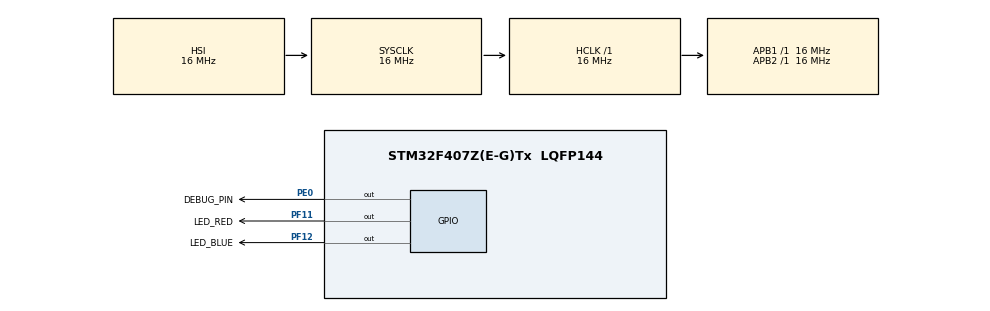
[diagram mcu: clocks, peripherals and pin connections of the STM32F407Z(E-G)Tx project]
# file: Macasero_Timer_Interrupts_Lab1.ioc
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Mcu.Family=STM32F4
Mcu.Name=STM32F407Z(E-G)Tx
Mcu.Package=LQFP144
NVIC.PriorityGroup=NVIC_PRIORITYGROUP_4
NVIC.TIM2_IRQn=true\:0\:0\:false\:false\:true\:true\:true\:true
NVIC.TIM3_IRQn=true\:0\:0\:false\:false\:true\:true\:true\:true
PE0.GPIO_Label=DEBUG_PIN
PE0.Signal=GPIO_Output
PF11.GPIO_Label=LED_RED
PF11.Signal=GPIO_Output
PF12.GPIO_Label=LED_BLUE
PF12.Signal=GPIO_Output
ProjectManager.HeapSize=0x200
ProjectManager.StackSize=0x400
ProjectManager.TargetToolchain=STM32CubeIDE
RCC.AHBFreq_Value=16000000
RCC.APB1Freq_Value=16000000
RCC.APB2Freq_Value=16000000
RCC.CortexFreq_Value=16000000
RCC.HSE_VALUE=25000000
RCC.HSI_VALUE=16000000
RCC.LSE_VALUE=32768
RCC.SYSCLKFreq_VALUE=16000000
RCC.VCOOutputFreq_Value=192000000
TIM2.Period=9999
TIM2.Prescaler=8399
TIM3.Period=4999
TIM3.Prescaler=8399
VP_TIM2_VS_ClockSourceINT.Mode=Internal
VP_TIM3_VS_ClockSourceINT.Mode=Internal
board=custom

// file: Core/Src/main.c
/* USER CODE BEGIN Header */
/**
  ******************************************************************************
  * @file           : main.c
  * @brief          : Main program body with DWT cycle counter
  ******************************************************************************
  * @attention
  *
  * Copyright (c) 2026 STMicroelectronics.
  * All rights reserved.
  *
  * This software is licensed under terms that can be found in the LICENSE file
  * in the root directory of this software component.
  * If no LICENSE file comes with this software, it is provided AS-IS.
  *
  ******************************************************************************
  */
/* USER CODE END Header */

#include "main.h"

TIM_HandleTypeDef htim2;
TIM_HandleTypeDef htim3;

/* USER CODE BEGIN PV */
/// Flags for foreground/background communication
volatile uint8_t task_adc_ready = 0;
volatile uint8_t task_display_ready = 0;
volatile uint32_t tick_count = 0;

/* USER CODE END PV */

void SystemClock_Config(void);
static void MX_GPIO_Init(void);
static void MX_TIM2_Init(void);
static void MX_TIM3_Init(void);

/* USER CODE BEGIN 0 */
// ------------------- DWT Cycle Counter for Microsecond Timing -------------------
static void DWT_Init(void) {
    if (!(CoreDebug->DEMCR & CoreDebug_DEMCR_TRCENA_Msk)) {
        CoreDebug->DEMCR |= CoreDebug_DEMCR_TRCENA_Msk; // Enable trace
    }
    DWT->CYCCNT = 0;            // Reset cycle counter
    DWT->CTRL |= DWT_CTRL_CYCCNTENA_Msk; // Enable cycle counter
}

static uint32_t DWT_GetMicroseconds(void) {
    return DWT->CYCCNT / (SystemCoreClock / 1000000);
}
// --------------------------------------------------------------------------------

// Timer Interrupt Callback
void HAL_TIM_PeriodElapsedCallback(TIM_HandleTypeDef *htim)
{
    if (htim->Instance == TIM2)
    {
        uint32_t start_us = DWT_GetMicroseconds();

        HAL_GPIO_WritePin(DEBUG_PIN_GPIO_Port, DEBUG_PIN_Pin, GPIO_PIN_SET);
        HAL_GPIO_TogglePin(LED_RED_GPIO_Port, LED_RED_Pin);
        task_adc_ready = 1;

        HAL_GPIO_WritePin(DEBUG_PIN_GPIO_Port, DEBUG_PIN_Pin, GPIO_PIN_RESET);

        uint32_t elapsed_us = DWT_GetMicroseconds() - start_us;
        // You can store or print elapsed_us if needed
    }
}
/* USER CODE END 0 */

int main(void)
{

    /* MCU Configuration--------------------------------------------------------*/
    HAL_Init();

    /* Configure the system clock */
    SystemClock_Config();

    /* Initialize all configured peripherals */
    MX_GPIO_Init();
    MX_TIM2_Init();
    MX_TIM3_Init();

    /* USER CODE BEGIN 2 */
    HAL_TIM_Base_Start_IT(&htim2);
    HAL_TIM_Base_Start_IT(&htim3);

    DWT_Init();  // Initialize DWT cycle counter
    /* USER CODE END 2 */

    /* Infinite loop */
    /* USER CODE BEGIN WHILE */
    while (1)
    {
        if (task_adc_ready)
        {
            uint32_t start_us = DWT_GetMicroseconds();

            HAL_GPIO_WritePin(DEBUG_PIN_GPIO_Port, DEBUG_PIN_Pin, GPIO_PIN_SET);
            task_adc_ready = 0;
            HAL_Delay(50); // Simulate ADC processing
            HAL_GPIO_WritePin(DEBUG_PIN_GPIO_Port, DEBUG_PIN_Pin, GPIO_PIN_RESET);

            uint32_t elapsed_us = DWT_GetMicroseconds() - start_us;
            // You can store or print elapsed_us if needed
        }
    }
    /* USER CODE END WHILE */

}

void SystemClock_Config(void)
{
    RCC_OscInitTypeDef RCC_OscInitStruct = {0};
    RCC_ClkInitTypeDef RCC_ClkInitStruct = {0};

    __HAL_RCC_PWR_CLK_ENABLE();
    __HAL_PWR_VOLTAGESCALING_CONFIG(PWR_REGULATOR_VOLTAGE_SCALE1);

    RCC_OscInitStruct.OscillatorType = RCC_OSCILLATORTYPE_HSI;
    RCC_OscInitStruct.HSIState = RCC_HSI_ON;
    RCC_OscInitStruct.HSICalibrationValue = RCC_HSICALIBRATION_DEFAULT;
    RCC_OscInitStruct.PLL.PLLState = RCC_PLL_NONE;
    if (HAL_RCC_OscConfig(&RCC_OscInitStruct) != HAL_OK)
    {
        Error_Handler();
    }

    RCC_ClkInitStruct.ClockType = RCC_CLOCKTYPE_HCLK|RCC_CLOCKTYPE_SYSCLK
                                |RCC_CLOCKTYPE_PCLK1|RCC_CLOCKTYPE_PCLK2;
    RCC_ClkInitStruct.SYSCLKSource = RCC_SYSCLKSOURCE_HSI;
    RCC_ClkInitStruct.AHBCLKDivider = RCC_SYSCLK_DIV1;
    RCC_ClkInitStruct.APB1CLKDivider = RCC_HCLK_DIV1;
    RCC_ClkInitStruct.APB2CLKDivider = RCC_HCLK_DIV1;

    if (HAL_RCC_ClockConfig(&RCC_ClkInitStruct, FLASH_LATENCY_0) != HAL_OK)
    {
        Error_Handler();
    }
}

static void MX_TIM2_Init(void)
{
    TIM_ClockConfigTypeDef sClockSourceConfig = {0};
    TIM_MasterConfigTypeDef sMasterConfig = {0};

    htim2.Instance = TIM2;
    htim2.Init.Prescaler = 8399;
    htim2.Init.CounterMode = TIM_COUNTERMODE_UP;
    htim2.Init.Period = 9999;
    htim2.Init.ClockDivision = TIM_CLOCKDIVISION_DIV1;
    htim2.Init.AutoReloadPreload = TIM_AUTORELOAD_PRELOAD_DISABLE;
    if (HAL_TIM_Base_Init(&htim2) != HAL_OK)
    {
        Error_Handler();
    }

    sClockSourceConfig.ClockSource = TIM_CLOCKSOURCE_INTERNAL;
    if (HAL_TIM_ConfigClockSource(&htim2, &sClockSourceConfig) != HAL_OK)
    {
        Error_Handler();
    }

    sMasterConfig.MasterOutputTrigger = TIM_TRGO_RESET;
    sMasterConfig.MasterSlaveMode = TIM_MASTERSLAVEMODE_DISABLE;
    if (HAL_TIMEx_MasterConfigSynchronization(&htim2, &sMasterConfig) != HAL_OK)
    {
        Error_Handler();
    }
}

static void MX_TIM3_Init(void)
{
    TIM_ClockConfigTypeDef sClockSourceConfig = {0};
    TIM_MasterConfigTypeDef sMasterConfig = {0};

    htim3.Instance = TIM3;
    htim3.Init.Prescaler = 8399;
    htim3.Init.CounterMode = TIM_COUNTERMODE_UP;
    htim3.Init.Period = 4999;
    htim3.Init.ClockDivision = TIM_CLOCKDIVISION_DIV1;
    htim3.Init.AutoReloadPreload = TIM_AUTORELOAD_PRELOAD_DISABLE;
    if (HAL_TIM_Base_Init(&htim3) != HAL_OK)
    {
        Error_Handler();
    }

    sClockSourceConfig.ClockSource = TIM_CLOCKSOURCE_INTERNAL;
    if (HAL_TIM_ConfigClockSource(&htim3, &sClockSourceConfig) != HAL_OK)
    {
        Error_Handler();
    }

    sMasterConfig.MasterOutputTrigger = TIM_TRGO_RESET;
    sMasterConfig.MasterSlaveMode = TIM_MASTERSLAVEMODE_DISABLE;
    if (HAL_TIMEx_MasterConfigSynchronization(&htim3, &sMasterConfig) != HAL_OK)
    {
        Error_Handler();
    }
}

static void MX_GPIO_Init(void)
{
    GPIO_InitTypeDef GPIO_InitStruct = {0};

    __HAL_RCC_GPIOF_CLK_ENABLE();
    __HAL_RCC_GPIOE_CLK_ENABLE();

    HAL_GPIO_WritePin(GPIOF, LED_RED_Pin|LED_BLUE_Pin, GPIO_PIN_RESET);
    HAL_GPIO_WritePin(DEBUG_PIN_GPIO_Port, DEBUG_PIN_Pin, GPIO_PIN_RESET);

    GPIO_InitStruct.Pin = LED_RED_Pin|LED_BLUE_Pin;
    GPIO_InitStruct.Mode = GPIO_MODE_OUTPUT_PP;
    GPIO_InitStruct.Pull = GPIO_NOPULL;
    GPIO_InitStruct.Speed = GPIO_SPEED_FREQ_LOW;
    HAL_GPIO_Init(GPIOF, &GPIO_InitStruct);

    GPIO_InitStruct.Pin = DEBUG_PIN_Pin;
    GPIO_InitStruct.Mode = GPIO_MODE_OUTPUT_PP;
    GPIO_InitStruct.Pull = GPIO_NOPULL;
    GPIO_InitStruct.Speed = GPIO_SPEED_FREQ_LOW;
    HAL_GPIO_Init(DEBUG_PIN_GPIO_Port, &GPIO_InitStruct);
}

void Error_Handler(void)
{
    __disable_irq();
    while (1)
    {
    }
}
